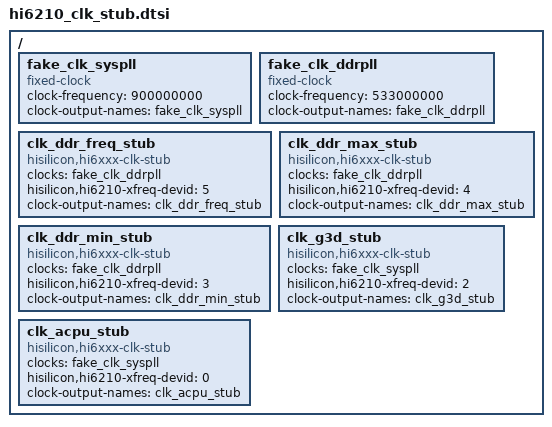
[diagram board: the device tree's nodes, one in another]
/******************************************************************************

                  版权所有 (C), 2001-2011, 华为技术有限公司

 ******************************************************************************
 
  This is an stub file !  Just for DDR ACPU GPU!
  文 件 名   : hi6210_clk_stub.dtsi
  生成日期   : 2014年3月24日
  
******************************************************************************/


/ {
	fake_clk_syspll: fake_clk_syspll {
		compatible = "fixed-clock";
		#clock-cells = <0>;
		clock-frequency = <900000000>;
		clock-output-names = "fake_clk_syspll";
	};
	fake_clk_ddrpll: fake_clk_ddrpll {
		compatible = "fixed-clock";
		#clock-cells = <0>;	
		clock-frequency = <533000000>;		
		clock-output-names = "fake_clk_ddrpll";
	};
	
	clk_ddr_freq_stub: clk_ddr_freq_stub {
		compatible = "hisilicon,hi6xxx-clk-stub";
		#clock-cells = <0>;
		clocks = <&fake_clk_ddrpll>;
		hisilicon,hi6210-xfreq-devid = <5>;
		clock-output-names = "clk_ddr_freq_stub";
	};
	
	clk_ddr_max_stub: clk_ddr_max_stub {
		compatible = "hisilicon,hi6xxx-clk-stub";
		#clock-cells = <0>;
		clocks = <&fake_clk_ddrpll>;
		hisilicon,hi6210-xfreq-devid = <4>;
		clock-output-names = "clk_ddr_max_stub";
	};
	
	clk_ddr_min_stub: clk_ddr_min_stub {
		compatible = "hisilicon,hi6xxx-clk-stub";
		#clock-cells = <0>;
		clocks = <&fake_clk_ddrpll>;
		hisilicon,hi6210-xfreq-devid = <3>;
		clock-output-names = "clk_ddr_min_stub";
	};
	
	clk_g3d_stub: clk_g3d_stub {
		compatible = "hisilicon,hi6xxx-clk-stub";
		#clock-cells = <0>;
		clocks = <&fake_clk_syspll>;
		hisilicon,hi6210-xfreq-devid = <2>;
		clock-output-names = "clk_g3d_stub";
	};
	
	clk_acpu_stub: clk_acpu_stub {
		compatible = "hisilicon,hi6xxx-clk-stub";
		#clock-cells = <0>;
		clocks = <&fake_clk_syspll>;
		hisilicon,hi6210-xfreq-devid = <0>;
		clock-output-names = "clk_acpu_stub";
	};
	
};
